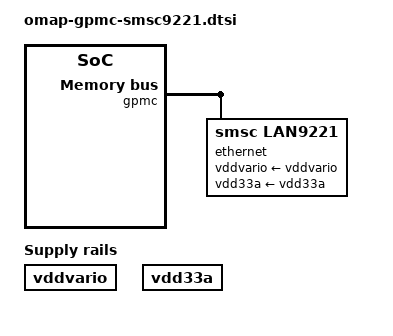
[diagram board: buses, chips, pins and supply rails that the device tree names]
/*
 * Common file for GPMC connected smsc9221 on omaps
 *
 * Compared to smsc911x, smsc9221 (and others like smsc9217
 * or smsc 9218) has faster timings, leading to higher
 * bandwidth.
 *
 * Note that the board specifc DTS file needs to specify
 * ranges, pinctrl, reg, interrupt parent and interrupts.
 */

/ {
	vddvario: regulator-vddvario {
		  compatible = "regulator-fixed";
		  regulator-name = "vddvario";
		  regulator-always-on;
	};

	vdd33a: regulator-vdd33a {
		compatible = "regulator-fixed";
		regulator-name = "vdd33a";
		regulator-always-on;
	};
};

&gpmc {
	ethernet@gpmc {
		compatible = "smsc,lan9221","smsc,lan9115";
		bank-width = <2>;

		gpmc,mux-add-data;
		gpmc,cs-on-ns = <0>;
		gpmc,cs-rd-off-ns = <42>;
		gpmc,cs-wr-off-ns = <36>;
		gpmc,adv-on-ns = <6>;
		gpmc,adv-rd-off-ns = <12>;
		gpmc,adv-wr-off-ns = <12>;
		gpmc,oe-on-ns = <0>;
		gpmc,oe-off-ns = <42>;
		gpmc,we-on-ns = <0>;
		gpmc,we-off-ns = <36>;
		gpmc,rd-cycle-ns = <60>;
		gpmc,wr-cycle-ns = <54>;
		gpmc,access-ns = <36>;
		gpmc,page-burst-access-ns = <0>;
		gpmc,bus-turnaround-ns = <0>;
		gpmc,cycle2cycle-delay-ns = <0>;
		gpmc,wr-data-mux-bus-ns = <18>;
		gpmc,wr-access-ns = <42>;
		gpmc,cycle2cycle-samecsen;
		gpmc,cycle2cycle-diffcsen;

		vddvario-supply = <&vddvario>;
		vdd33a-supply = <&vdd33a>;
		reg-io-width = <4>;
		smsc,save-mac-address;
	};
};
